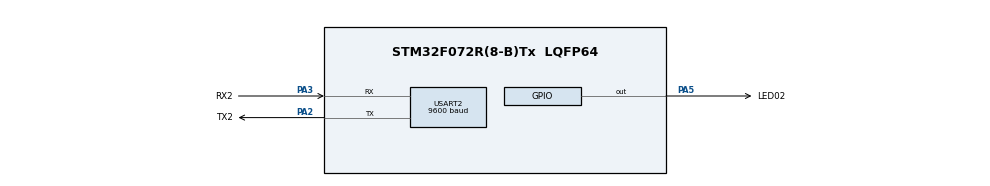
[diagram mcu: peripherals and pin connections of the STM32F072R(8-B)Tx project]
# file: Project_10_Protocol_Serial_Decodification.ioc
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Mcu.Family=STM32F0
Mcu.Name=STM32F072R(8-B)Tx
Mcu.Package=LQFP64
NVIC.USART2_IRQn=true\:0\:0\:false\:false\:true\:true\:true\:true
PA2.GPIO_Label=TX2
PA2.Mode=Asynchronous
PA2.Signal=USART2_TX
PA3.GPIO_Label=RX2
PA3.Mode=Asynchronous
PA3.Signal=USART2_RX
PA5.GPIO_Label=LED02
PA5.Signal=GPIO_Output
ProjectManager.HeapSize=0x200
ProjectManager.StackSize=0x400
ProjectManager.TargetToolchain=STM32CubeIDE
USART2.BaudRate=9600
USART2.VirtualMode-Asynchronous=VM_ASYNC
board=custom

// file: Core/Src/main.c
/* USER CODE BEGIN Header */
/**
  ******************************************************************************
  * @file           : main.c
  * @brief          : Main program body
  ******************************************************************************
  * @attention
  *
  * Copyright (c) 2022 STMicroelectronics.
  * All rights reserved.
  *
  * This software is licensed under terms that can be found in the LICENSE file
  * in the root directory of this software component.
  * If no LICENSE file comes with this software, it is provided AS-IS.
  *
  ******************************************************************************
  */
/* USER CODE END Header */
#include "main.h"

/* USER CODE BEGIN Includes */
#include <stdio.h>
#include <stdlib.h>

/* USER CODE END Includes */

/* USER CODE BEGIN PD */

#define ESTAGIO_PREPROSESSAMENTO 0
#define ESTAGIO_01 1
#define ESTAGIO_02 2
#define ESTAGIO_03 3
#define ESTAGIO_04 4
#define ESTAGIO_05 5
#define CABECALHO  6
#define LED_HIGH HAL_GPIO_WritePin(GPIOA, LED02_Pin, GPIO_PIN_SET)
#define LED_LOW HAL_GPIO_WritePin(GPIOA, LED02_Pin, GPIO_PIN_RESET)
#define DELAY HAL_Delay(500)

/* USER CODE END PD */

UART_HandleTypeDef huart2;

void SystemClock_Config(void);
static void MX_GPIO_Init(void);
static void MX_USART2_UART_Init(void);

/* USER CODE BEGIN PFP */

int PiscaLed(int NumPiscadas , int TempoDelay)
{

	for(int i = 0; i < NumPiscadas; i++)
	{

		HAL_GPIO_WritePin(GPIOA,LED02_Pin,GPIO_PIN_SET);
		HAL_Delay(TempoDelay);
		HAL_GPIO_WritePin(GPIOA,LED02_Pin,GPIO_PIN_RESET);
		HAL_Delay(TempoDelay);

	}

	return 0;

}

void checkSum(uint8_t *Byte, int tamanho)
{
	//Adicionar uma vriável chamda tamanho para controlar até onde o for irá

	unsigned char dados[1]= {0};

	unsigned char *pointer;

	//int posicao = 0;

	pointer = &dados[1];

	for (int i = 0; i < tamanho; i++)
	{

		if (Byte[i] != 0)

		{

			HAL_Delay(100);
			dados[1] = dados[1] + Byte[i];

		}

		else
		{
			break;

		}

	}

	HAL_UART_Transmit(&huart2,pointer,1,100);

	for (int y = 0; y < tamanho; y++ )
	{

		Byte[y] = 0;

		if (y < 2)
		{

			dados[y] = 0;

		}

	}

	tamanho  = 0;

}

/* USER CODE END PFP */

int main(void)
{

  /* MCU Configuration--------------------------------------------------------*/

  /* Reset of all peripherals, Initializes the Flash interface and the Systick. */
  HAL_Init();

  /* USER CODE BEGIN Init */

  HAL_StatusTypeDef rx_status;
  int Tamanho_string = 0;

  /* USER CODE END Init */

  /* Configure the system clock */
  SystemClock_Config();

  /* Initialize all configured peripherals */
  MX_GPIO_Init();
  MX_USART2_UART_Init();

  /* Infinite loop */
  while (1)
  {

	  HAL_Delay(500);

	  uint8_t rx_dados[12] = {0};

	  rx_status = HAL_UART_Receive_IT(&huart2,rx_dados,12);

	  HAL_Delay(500);

	  Tamanho_string = sizeof(rx_dados);

	  if (rx_status !=  HAL_ERROR && rx_dados[0] != 0)
	  {
		  checkSum(rx_dados,Tamanho_string);
	  }

  }
}

void SystemClock_Config(void)
{
  RCC_OscInitTypeDef RCC_OscInitStruct = {0};
  RCC_ClkInitTypeDef RCC_ClkInitStruct = {0};
  RCC_PeriphCLKInitTypeDef PeriphClkInit = {0};

  /** Initializes the RCC Oscillators according to the specified parameters
  * in the RCC_OscInitTypeDef structure.
  */
  RCC_OscInitStruct.OscillatorType = RCC_OSCILLATORTYPE_HSI;
  RCC_OscInitStruct.HSIState = RCC_HSI_ON;
  RCC_OscInitStruct.HSICalibrationValue = RCC_HSICALIBRATION_DEFAULT;
  RCC_OscInitStruct.PLL.PLLState = RCC_PLL_NONE;
  if (HAL_RCC_OscConfig(&RCC_OscInitStruct) != HAL_OK)
  {
    Error_Handler();
  }

  /** Initializes the CPU, AHB and APB buses clocks
  */
  RCC_ClkInitStruct.ClockType = RCC_CLOCKTYPE_HCLK|RCC_CLOCKTYPE_SYSCLK
                              |RCC_CLOCKTYPE_PCLK1;
  RCC_ClkInitStruct.SYSCLKSource = RCC_SYSCLKSOURCE_HSI;
  RCC_ClkInitStruct.AHBCLKDivider = RCC_SYSCLK_DIV1;
  RCC_ClkInitStruct.APB1CLKDivider = RCC_HCLK_DIV1;

  if (HAL_RCC_ClockConfig(&RCC_ClkInitStruct, FLASH_LATENCY_0) != HAL_OK)
  {
    Error_Handler();
  }
  PeriphClkInit.PeriphClockSelection = RCC_PERIPHCLK_USART2;
  PeriphClkInit.Usart2ClockSelection = RCC_USART2CLKSOURCE_PCLK1;
  if (HAL_RCCEx_PeriphCLKConfig(&PeriphClkInit) != HAL_OK)
  {
    Error_Handler();
  }
}

static void MX_USART2_UART_Init(void)
{

  huart2.Instance = USART2;
  huart2.Init.BaudRate = 9600;
  huart2.Init.WordLength = UART_WORDLENGTH_8B;
  huart2.Init.StopBits = UART_STOPBITS_1;
  huart2.Init.Parity = UART_PARITY_NONE;
  huart2.Init.Mode = UART_MODE_TX_RX;
  huart2.Init.HwFlowCtl = UART_HWCONTROL_NONE;
  huart2.Init.OverSampling = UART_OVERSAMPLING_16;
  huart2.Init.OneBitSampling = UART_ONE_BIT_SAMPLE_DISABLE;
  huart2.AdvancedInit.AdvFeatureInit = UART_ADVFEATURE_NO_INIT;
  if (HAL_UART_Init(&huart2) != HAL_OK)
  {
    Error_Handler();
  }

}

static void MX_GPIO_Init(void)
{
  GPIO_InitTypeDef GPIO_InitStruct = {0};

  /* GPIO Ports Clock Enable */
  __HAL_RCC_GPIOA_CLK_ENABLE();

  /*Configure GPIO pin Output Level */
  HAL_GPIO_WritePin(LED02_GPIO_Port, LED02_Pin, GPIO_PIN_RESET);

  /*Configure GPIO pin : LED02_Pin */
  GPIO_InitStruct.Pin = LED02_Pin;
  GPIO_InitStruct.Mode = GPIO_MODE_OUTPUT_PP;
  GPIO_InitStruct.Pull = GPIO_NOPULL;
  GPIO_InitStruct.Speed = GPIO_SPEED_FREQ_LOW;
  HAL_GPIO_Init(LED02_GPIO_Port, &GPIO_InitStruct);

}

void Error_Handler(void)
{
  __disable_irq();
  while (1)
  {
  }
}
